AUTOSAR XML (schema 4-1-1)
package /E2E_InterSWC_1
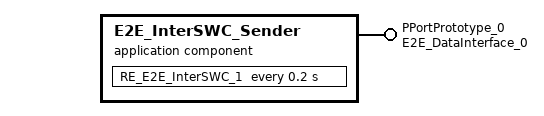
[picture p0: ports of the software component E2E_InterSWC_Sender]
  application sw component type E2E_InterSWC_Sender
    provide port PPortPrototype_0: provided-interface=E2E_DataInterface_0
    behavior IB_E2E_InterSWC_1
      timing event E2E_InterSWC_1_Event: start-on-event=RE_E2E_InterSWC_1, period=0.2
      runnable RE_E2E_InterSWC_1: symbol=E2E_InterSWC_1_REProc
        data-send-points:
          access DSP_CKS_0: accessed-variable=PPortPrototype_0.CKS
          access DSP_Alive_Cnt_0: accessed-variable=PPortPrototype_0.Alive_Cnt
          access DSP_Data_0: accessed-variable=PPortPrototype_0.Data
  data type mapping set DataTypeMappingSet_E2E
